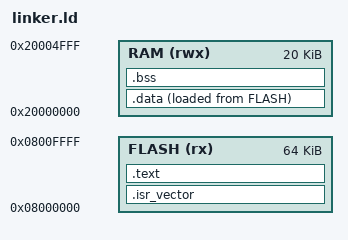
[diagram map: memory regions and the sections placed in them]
ENTRY(Reset_Handler)

MEMORY
{
    FLASH (rx)  : ORIGIN = 0x08000000, LENGTH = 64K
    RAM   (rwx) : ORIGIN = 0x20000000, LENGTH = 20K
}

__stack_top = ORIGIN(RAM) + LENGTH(RAM);

SECTIONS
{
    .isr_vector :
    {
        . = ALIGN(4);
        KEEP(*(.isr_vector))
        KEEP(*(.isr_vector.*))
        . = ALIGN(4);
    } > FLASH

    .text :
    {
        . = ALIGN(4);
        *(.text)
        *(.text.*)
        *(.rodata)
        *(.rodata.*)
        . = ALIGN(4);
        _etext = .;
    } > FLASH

    .data :
    {
        . = ALIGN(4);
        __data_start = .;
        *(.data)
        *(.data.*)
        . = ALIGN(4);
        __data_end = .;
    } > RAM AT > FLASH

    __data_load = LOADADDR(.data);

    .bss :
    {
        . = ALIGN(4);
        __bss_start = .;
        *(.bss)
        *(.bss.*)
        *(COMMON)
        . = ALIGN(4);
        __bss_end = .;
    } > RAM

    /DISCARD/ :
    {
        *(.ARM.exidx*)
        *(.ARM.extab*)
        *(.eh_frame*)
    }
}
